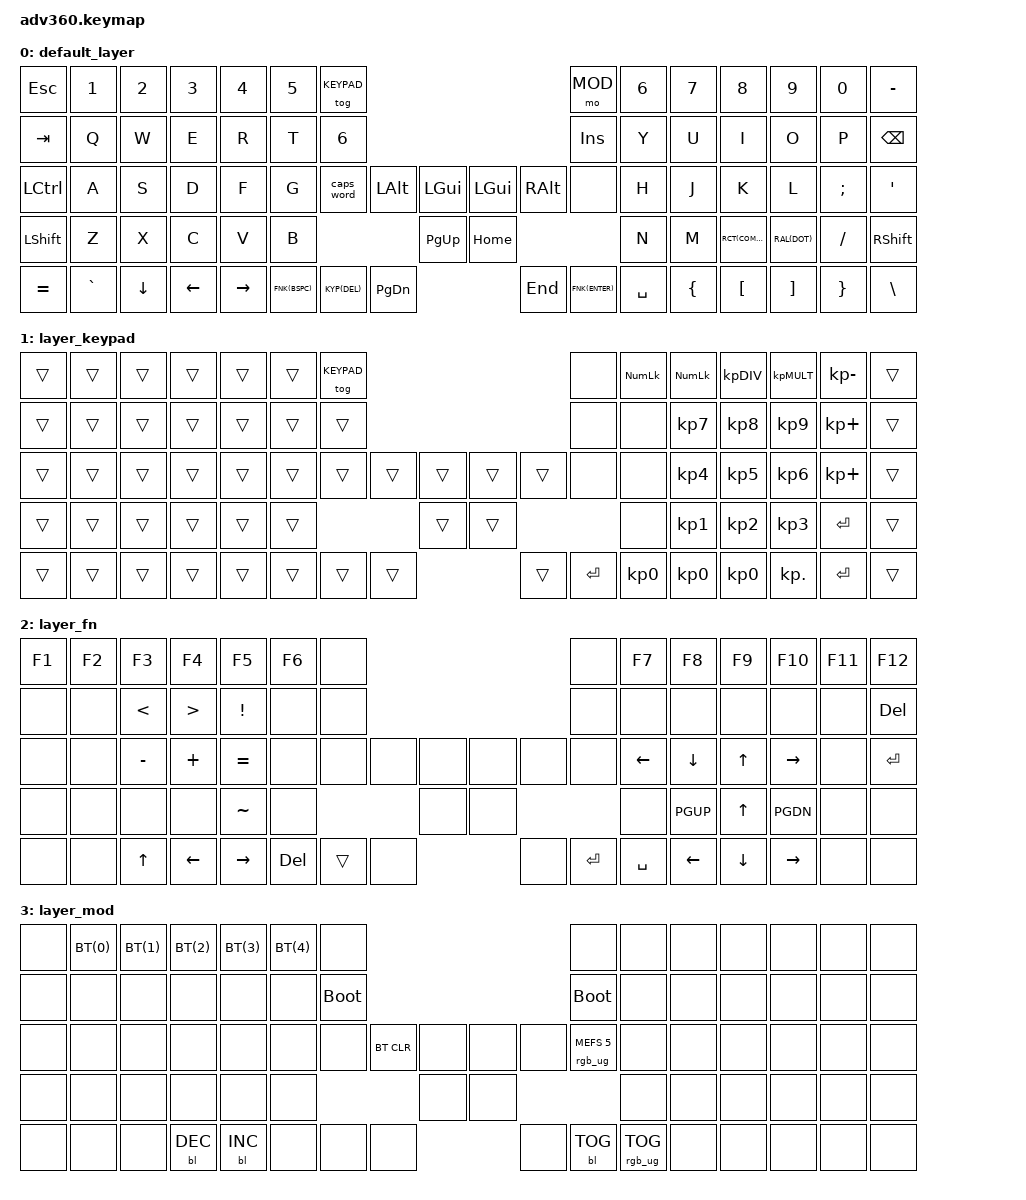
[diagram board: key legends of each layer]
#include <behaviors.dtsi>
#include <dt-bindings/zmk/keys.h>
#include <dt-bindings/zmk/bt.h>
#include <dt-bindings/zmk/rgb.h>
#include <dt-bindings/zmk/backlight.h>

// Layer definitions
#define DEFAULT 0
#define KEYPAD  1
#define FN      2
#define MOD     3

// Shift key hold-tap macro, homerow mod
#define LSH(k)  &hm LSHFT k
#define RSH(k)  &hm RSHFT k

// Control key hold-tap macro, homerow mod
#define LCT(k)  &hm LCTRL k
#define RCT(k)  &hm RCTRL k

// Alt key hold-tap macro, homerow mod
#define LAL(k)  &hm LALT k
#define RAL(k)  &hm RALT k

// GUI key hold-tap macro, homerow mod
#define LGU(k)  &hm LGUI k
#define RGU(k)  &hm RGUI k

// Layer FN hold-tap macro
#define FNK(k)  &lt FN k

// Layer KEYPAD hold-tap macro
#define KYP(k)  &lt KEYPAD k

// Bluetooth macro to tidy up the layout
#define BT(k)   &bt BT_SEL k

// backlight / led macros
#define T_BL    &bl BL_TOG      // toggle backlight
#define T_LED   &rgb_ug RGB_TOG // toggle status LEDs
#define BL_UP   &bl BL_INC      // backlight level increase
#define BL_DN   &bl BL_DEC      // backlight level decrease

// Keypad shorteners
#define KP_DIV  KP_DIVIDE
#define KP_MULT KP_MULTIPLY

// Misc macros to tidy up the layout
#define M_BOOT  &bootloader
#define M_CAPS  &caps_word
#define M_CHCK  &rgb_ug RGB_MEFS_CMD 5   // battery level check

/ {
    behaviors {
      #include "macros.dtsi"
      #include "version.dtsi"
      #ifndef VERSION_MACRO
      macro_ver: macro_ver {
        compatible = "zmk,behavior-macro";
        label = "macro_version";
        #binding-cells = <0>;
        bindings = <&kp RET>;
      };
      #endif

      hm: homerow_mods {
          compatible = "zmk,behavior-hold-tap";
          label = "HOMEROW_MODS";
          #binding-cells = <2>;
          tapping-term-ms = <200>;
          quick_tap_ms = <175>;
          flavor = "tap-preferred";
          bindings = <&kp>, <&kp>;
      };

      lh_pht: left_hand_positional_hold_tap {
        compatible = "zmk,behavior-hold-tap";
        label = "LEFT_POSITIONAL_HOLD_TAP";
        #binding-cells = <2>;
        flavor = "tap-unless-interrupted";
        tapping-term-ms = <100>;
        quick-tap-ms = <200>;
        bindings = <&kp>, <&kp>;
        hold-trigger-key-positions = <7 8 9 10 11 12 13  21 22 23 24 25 26 27  37 38 39 40 41 42 43 44 45  53 54 55 56 57 58 59  68 69 70 71 72 73 74 75>;
      };

      rh_pht: right_hand_positional_hold_tap {
        compatible = "zmk,behavior-hold-tap";
        label = "RIGHT_POSITIONAL_HOLD_TAP";
        #binding-cells = <2>;
        flavor = "tap-unless-interrupted";
        tapping-term-ms = <100>;
        quick-tap-ms = <200>;
        bindings = <&kp>, <&kp>;
        hold-trigger-key-positions = <0 1 2 3 4 5 6  14 15 16 17 18 19 20  28 29 30 31 32 33 34 35 36  46 47 48 49 50 51 52  60 61 62 63 64 65 66 67>;
      };
    };


    keymap {
        compatible = "zmk,keymap";


        default_layer {
            bindings = <
// pos 0   pos 1     pos 2     pos 3     pos 4   pos 5    pos 6                            //                               pos 7   pos 8      pos 9       pos 10       pos 11      pos 12       pos 13
&kp ESC    &kp N1    &kp N2    &kp N3    &kp N4  &kp N5   &tog KEYPAD                                                       &mo MOD &kp N6     &kp N7      &kp N8       &kp N9      &kp N0       &kp MINUS
&kp TAB    &kp Q     &kp W     &kp E     &kp R   &kp T    &kp N6                                                            &kp INS &kp Y      &kp U       &kp I        &kp O       &kp P        &kp BSPC

// pos 28  pos 29    pos 30    pos 31    pos 32  pos 33   pos 34     pos 35      pos 36    //pos 37     pos 38              pos 39  pos 40     pos 41      pos 42       pos 43      pos 44       pos 45
&kp LCTRL  &kp A     &kp S     &kp D     &kp F   &kp G    M_CAPS     &kp LALT    &kp LGUI    &kp LGUI   &kp RALT            &none   &kp H      &kp J       &kp K        &kp L       &kp SEMI     &kp SQT
&kp LSHFT  &kp Z     &kp X     &kp C     &kp V   &kp B                           &kp PG_UP   &kp HOME                               &kp N      &kp M       RCT(COMMA)   RAL(DOT)    &kp FSLH     &kp RSHFT
&kp EQUAL  &kp GRAVE &kp DOWN  &kp LEFT  &kp RIGHT        FNK(BSPC)  KYP(DEL)    &kp PG_DN   &kp END    FNK(ENTER) &kp SPACE                   &kp LBRC    &kp LBKT     &kp RBKT    &kp RBRC     &kp BSLH
            >;
        };

        layer_keypad {
            bindings = <
&trans     &trans    &trans    &trans    &trans  &trans   &tog KEYPAD                                                      &none   &kp KP_NLCK &kp KP_NLCK &kp KP_DIV   &kp KP_MULT &kp KP_MINUS &trans
&trans     &trans    &trans    &trans    &trans  &trans   &trans                                                           &none   &none       &kp KP_N7   &kp KP_N8    &kp KP_N9   &kp KP_PLUS  &trans
&trans     &trans    &trans    &trans    &trans  &trans   &trans    &trans       &trans      &trans     &trans             &none   &none       &kp KP_N4   &kp KP_N5    &kp KP_N6   &kp KP_PLUS  &trans
&trans     &trans    &trans    &trans    &trans  &trans                          &trans      &trans                                &none       &kp KP_N1   &kp KP_N2    &kp KP_N3   &kp ENTER    &trans
&trans     &trans    &trans    &trans    &trans           &trans    &trans       &trans      &trans     &kp ENTER  &kp KP_N0                   &kp KP_N0   &kp KP_N0    &kp KP_DOT  &kp ENTER    &trans
            >;
        };

        layer_fn {
            bindings = <
&kp F1     &kp F2    &kp F3    &kp F4    &kp F5    &kp F6   &none                                                          &none   &kp F7     &kp F8     &kp F9       &kp F10     &kp F11      &kp F12
&none      &none     &kp LT    &kp GT    &kp EXCL  &none    &none                                                          &none   &none      &none      &none        &none       &none        &kp DEL
&none      &none     &kp MINUS &kp PLUS  &kp EQUAL &none    &none     &none      &none       &none      &none              &none   &kp LEFT   &kp DOWN   &kp UP       &kp RIGHT   &none        &kp ENTER
&none      &none     &none     &none     &kp TILDE &none                         &none       &none                                 &none      &kp PGUP   &kp UP       &kp PGDN    &none        &none 
&none      &none     &kp UP    &kp LEFT  &kp RIGHT          &kp DEL   &trans     &none       &none      &kp ENTER  &kp SPACE                  &kp LEFT   &kp DOWN     &kp RIGHT   &none        &none
            >;
        };

        layer_mod {
            bindings = <
&none      BT(0)     BT(1)     BT(2)     BT(3)  BT(4)     &none                                                            &none   &none      &none      &none        &none      &none      &none
&none      &none     &none     &none     &none  &none     M_BOOT                                                           M_BOOT  &none      &none      &none        &none      &none      &none
&none      &none     &none     &none     &none  &none     &none     &bt BT_CLR &none       &none      &none                M_CHCK  &none      &none      &none        &none      &none      &none
&none      &none     &none     &none     &none  &none                          &none       &none                                   &none      &none      &none        &none      &none      &none
&none      &none     &none     BL_DN     BL_UP            &none     &none      &none       &none      T_BL       T_LED                        &none      &none        &none      &none      &none
            >;
        };
    };
};
